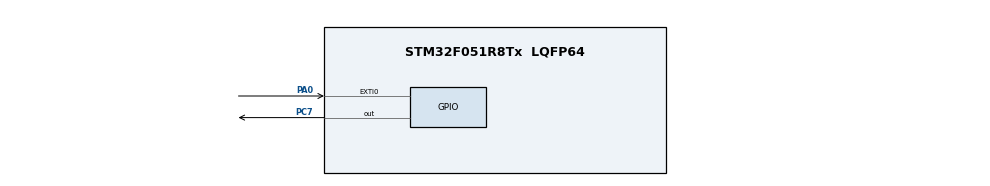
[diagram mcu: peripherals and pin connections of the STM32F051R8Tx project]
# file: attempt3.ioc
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Mcu.Family=STM32F0
Mcu.Name=STM32F051R8Tx
Mcu.Package=LQFP64
NVIC.EXTI0_1_IRQn=true\:0\:0\:false\:true\:true\:1\:true
NVIC.TIM3_IRQn=true\:0\:0\:false\:true\:true\:2\:true
PA0.Signal=GPXTI0
PC7.Signal=GPIO_Output
ProjectManager.HeapSize=0x200
ProjectManager.StackSize=0x400
ProjectManager.TargetToolchain=MDK-ARM V5
TIM3.Period=1000-1
TIM3.Prescaler=48000-1
VP_TIM3_VS_ClockSourceINT.Mode=Internal
board=custom

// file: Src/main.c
/**
  ******************************************************************************
  * @file           : main.c
  * @brief          : Main program body
  ******************************************************************************
  ** This notice applies to any and all portions of this file
  * that are not between comment pairs USER CODE BEGIN and
  * USER CODE END. Other portions of this file, whether
  * inserted by the user or by software development tools
  * are owned by their respective copyright owners.
  *
  * COPYRIGHT(c) 2018 STMicroelectronics
  *
  * Redistribution and use in source and binary forms, with or without modification,
  * are permitted provided that the following conditions are met:
  *   1. Redistributions of source code must retain the above copyright notice,
  *      this list of conditions and the following disclaimer.
  *   2. Redistributions in binary form must reproduce the above copyright notice,
  *      this list of conditions and the following disclaimer in the documentation
  *      and/or other materials provided with the distribution.
  *   3. Neither the name of STMicroelectronics nor the names of its contributors
  *      may be used to endorse or promote products derived from this software
  *      without specific prior written permission.
  *
  * THIS SOFTWARE IS PROVIDED BY THE COPYRIGHT HOLDERS AND CONTRIBUTORS "AS IS"
  * AND ANY EXPRESS OR IMPLIED WARRANTIES, INCLUDING, BUT NOT LIMITED TO, THE
  * IMPLIED WARRANTIES OF MERCHANTABILITY AND FITNESS FOR A PARTICULAR PURPOSE ARE
  * DISCLAIMED. IN NO EVENT SHALL THE COPYRIGHT HOLDER OR CONTRIBUTORS BE LIABLE
  * FOR ANY DIRECT, INDIRECT, INCIDENTAL, SPECIAL, EXEMPLARY, OR CONSEQUENTIAL
  * DAMAGES (INCLUDING, BUT NOT LIMITED TO, PROCUREMENT OF SUBSTITUTE GOODS OR
  * SERVICES; LOSS OF USE, DATA, OR PROFITS; OR BUSINESS INTERRUPTION) HOWEVER
  * CAUSED AND ON ANY THEORY OF LIABILITY, WHETHER IN CONTRACT, STRICT LIABILITY,
  * OR TORT (INCLUDING NEGLIGENCE OR OTHERWISE) ARISING IN ANY WAY OUT OF THE USE
  * OF THIS SOFTWARE, EVEN IF ADVISED OF THE POSSIBILITY OF SUCH DAMAGE.
  *
  ******************************************************************************
  */
#include "main.h"
#include "stm32f0xx_hal.h"

/* USER CODE BEGIN Includes */
#define DEBOUNCETIME 30
/* USER CODE END Includes */

TIM_HandleTypeDef htim3;

/* USER CODE BEGIN PV */
/* Private variables ---------------------------------------------------------*/
uint16_t oldTimerVal, newTimerval;
uint8_t buttonPressedDebounced = 0;
/* USER CODE END PV */

void SystemClock_Config(void);
static void MX_GPIO_Init(void);
static void MX_TIM3_Init(void);
static void MX_NVIC_Init(void);

/* USER CODE BEGIN PFP */
/* Private function prototypes -----------------------------------------------*/
void HAL_GPIO_EXTI_Callback(uint16_t GPIO_Pin);
void HAL_TIM_IC_CaptureCallback(TIM_HandleTypeDef *htim);
/* USER CODE END PFP */

int main(void)
{
  /* USER CODE BEGIN 1 */
	oldTimerVal = 0;
	newTimerval = 0;
  /* USER CODE END 1 */

  /* MCU Configuration----------------------------------------------------------*/

  /* Reset of all peripherals, Initializes the Flash interface and the Systick. */
  HAL_Init();

  /* Configure the system clock */
  SystemClock_Config();

  /* Initialize all configured peripherals */
  MX_GPIO_Init();
  MX_TIM3_Init();

  /* Initialize interrupts */
  MX_NVIC_Init();
  /* USER CODE BEGIN 2 */
	HAL_GPIO_WritePin(GPIOC, GPIO_PIN_9, GPIO_PIN_SET);
  /* USER CODE END 2 */

  /* Infinite loop */
  /* USER CODE BEGIN WHILE */
  while (1)
  {
		if(buttonPressedDebounced){
			HAL_GPIO_TogglePin(GPIOC, GPIO_PIN_9);
			buttonPressedDebounced = 0;
		}
  /* USER CODE END WHILE */

  }

}

void HAL_GPIO_EXTI_Callback(uint16_t GPIO_Pin){
	if(GPIO_Pin == GPIO_PIN_0){
		if((oldTimerVal>newTimerval) && ((oldTimerVal-newTimerval)<990)){
			buttonPressedDebounced = 1;
		}else{
			if(!oldTimerVal && !newTimerval){
				newTimerval = TIM3->ARR;
				buttonPressedDebounced = 1;
			}else{
				oldTimerVal = newTimerval;
				newTimerval = TIM3->ARR;
				if((newTimerval - oldTimerVal)>DEBOUNCETIME){
					buttonPressedDebounced = 1;
				}
			}
		}
	}
	TIM3->ARR = 0;
}

void HAL_TIM_IC_CaptureCallback(TIM_HandleTypeDef *htim){
	TIM3->ARR = 0;
}
void SystemClock_Config(void)
{

  RCC_OscInitTypeDef RCC_OscInitStruct;
  RCC_ClkInitTypeDef RCC_ClkInitStruct;

    /**Initializes the CPU, AHB and APB busses clocks
    */
  RCC_OscInitStruct.OscillatorType = RCC_OSCILLATORTYPE_HSI;
  RCC_OscInitStruct.HSIState = RCC_HSI_ON;
  RCC_OscInitStruct.HSICalibrationValue = 16;
  RCC_OscInitStruct.PLL.PLLState = RCC_PLL_NONE;
  if (HAL_RCC_OscConfig(&RCC_OscInitStruct) != HAL_OK)
  {
    _Error_Handler(__FILE__, __LINE__);
  }

    /**Initializes the CPU, AHB and APB busses clocks
    */
  RCC_ClkInitStruct.ClockType = RCC_CLOCKTYPE_HCLK|RCC_CLOCKTYPE_SYSCLK
                              |RCC_CLOCKTYPE_PCLK1;
  RCC_ClkInitStruct.SYSCLKSource = RCC_SYSCLKSOURCE_HSI;
  RCC_ClkInitStruct.AHBCLKDivider = RCC_SYSCLK_DIV1;
  RCC_ClkInitStruct.APB1CLKDivider = RCC_HCLK_DIV1;

  if (HAL_RCC_ClockConfig(&RCC_ClkInitStruct, FLASH_LATENCY_0) != HAL_OK)
  {
    _Error_Handler(__FILE__, __LINE__);
  }

    /**Configure the Systick interrupt time
    */
  HAL_SYSTICK_Config(HAL_RCC_GetHCLKFreq()/1000);

    /**Configure the Systick
    */
  HAL_SYSTICK_CLKSourceConfig(SYSTICK_CLKSOURCE_HCLK);

  /* SysTick_IRQn interrupt configuration */
  HAL_NVIC_SetPriority(SysTick_IRQn, 0, 0);
}

/**
  * @brief NVIC Configuration.
  * @retval None
  */
static void MX_NVIC_Init(void)
{
  /* EXTI0_1_IRQn interrupt configuration */
  HAL_NVIC_SetPriority(EXTI0_1_IRQn, 0, 0);
  HAL_NVIC_EnableIRQ(EXTI0_1_IRQn);
  /* TIM3_IRQn interrupt configuration */
  HAL_NVIC_SetPriority(TIM3_IRQn, 0, 0);
  HAL_NVIC_EnableIRQ(TIM3_IRQn);
}

/* TIM3 init function */
static void MX_TIM3_Init(void)
{

  TIM_ClockConfigTypeDef sClockSourceConfig;
  TIM_MasterConfigTypeDef sMasterConfig;

  htim3.Instance = TIM3;
  htim3.Init.Prescaler = 48000-1;
  htim3.Init.CounterMode = TIM_COUNTERMODE_UP;
  htim3.Init.Period = 1000-1;
  htim3.Init.ClockDivision = TIM_CLOCKDIVISION_DIV1;
  htim3.Init.AutoReloadPreload = TIM_AUTORELOAD_PRELOAD_DISABLE;
  if (HAL_TIM_Base_Init(&htim3) != HAL_OK)
  {
    _Error_Handler(__FILE__, __LINE__);
  }

  sClockSourceConfig.ClockSource = TIM_CLOCKSOURCE_INTERNAL;
  if (HAL_TIM_ConfigClockSource(&htim3, &sClockSourceConfig) != HAL_OK)
  {
    _Error_Handler(__FILE__, __LINE__);
  }

  sMasterConfig.MasterOutputTrigger = TIM_TRGO_RESET;
  sMasterConfig.MasterSlaveMode = TIM_MASTERSLAVEMODE_DISABLE;
  if (HAL_TIMEx_MasterConfigSynchronization(&htim3, &sMasterConfig) != HAL_OK)
  {
    _Error_Handler(__FILE__, __LINE__);
  }

}

/** Configure pins as
        * Analog
        * Input
        * Output
        * EVENT_OUT
        * EXTI
*/
static void MX_GPIO_Init(void)
{

  GPIO_InitTypeDef GPIO_InitStruct;

  /* GPIO Ports Clock Enable */
  __HAL_RCC_GPIOA_CLK_ENABLE();
  __HAL_RCC_GPIOC_CLK_ENABLE();

  /*Configure GPIO pin Output Level */
  HAL_GPIO_WritePin(GPIOC, GPIO_PIN_9, GPIO_PIN_RESET);

  /*Configure GPIO pin : PA0 */
  GPIO_InitStruct.Pin = GPIO_PIN_0;
  GPIO_InitStruct.Mode = GPIO_MODE_IT_RISING;
  GPIO_InitStruct.Pull = GPIO_NOPULL;
  HAL_GPIO_Init(GPIOA, &GPIO_InitStruct);

  /*Configure GPIO pin : PC9 */
  GPIO_InitStruct.Pin = GPIO_PIN_9;
  GPIO_InitStruct.Mode = GPIO_MODE_OUTPUT_PP;
  GPIO_InitStruct.Pull = GPIO_NOPULL;
  GPIO_InitStruct.Speed = GPIO_SPEED_FREQ_LOW;
  HAL_GPIO_Init(GPIOC, &GPIO_InitStruct);

}

void _Error_Handler(char *file, int line)
{
  while(1)
  {
  }
}

/************************ (C) COPYRIGHT STMicroelectronics *****END OF FILE****/
